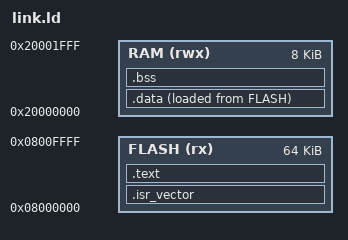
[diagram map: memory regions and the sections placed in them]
/* STM32F103C8 ("Blue Pill") / STM32F100 (VL Discovery, what QEMU emulates) share this map:
   64 KB of flash at 0x08000000 and, to run on both, the 8 KB of RAM they have in common. */
MEMORY
{
    FLASH (rx)  : ORIGIN = 0x08000000, LENGTH = 64K
    RAM   (rwx) : ORIGIN = 0x20000000, LENGTH = 8K
}

ENTRY(Reset_Handler)

SECTIONS
{
    .isr_vector : { KEEP(*(.isr_vector)) } > FLASH

    .text : {
        *(.text*)
        *(.rodata*)
        . = ALIGN(4);
    } > FLASH

    _sidata = LOADADDR(.data);

    .data : {
        _sdata = .;
        *(.data*)
        . = ALIGN(4);
        _edata = .;
    } > RAM AT> FLASH

    .bss : {
        _sbss = .;
        *(.bss*)
        *(COMMON)
        . = ALIGN(4);
        _ebss = .;
    } > RAM

    _estack = ORIGIN(RAM) + LENGTH(RAM);   /* the stack grows down from the top of RAM */

    /DISCARD/ : { *(.ARM.exidx*) *(.ARM.attributes*) }
}
